# MSP430FR6972 register map
Registers are 16-bit, read-write, reset 0x0 unless marked. A register's access mark holds for its fields unless they carry their own. Offsets are from the block's base; [hi:lo] are bit positions; {n}, {i} and the like mark numbered series.

## USCI_B1_SPI_MODE
Base 0x00000680
0x00 UCB1CTL1_SPI 8-bit — USCI B1 Control Register 1
0x01 UCB1CTL0_SPI 8-bit — USCI B1 Control Register 0
0x06 UCB1BR0_SPI 8-bit — USCI B1 Baud Rate 0
0x07 UCB1BR1_SPI 8-bit — USCI B1 Baud Rate 1
0x0C UCB1RXBUF_SPI — USCI B1 Receive Buffer
0x0E UCB1TXBUF_SPI — USCI B1 Transmit Buffer
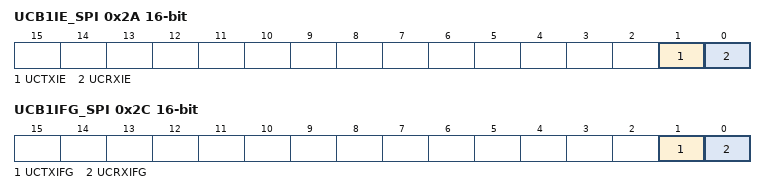
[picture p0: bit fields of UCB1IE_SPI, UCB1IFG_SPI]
0x2A UCB1IE_SPI — USCI B1 Interrupt Enable Register
  [1] UCTXIE — USCI Transmit Interrupt Enable
  [0] UCRXIE — USCI Receive Interrupt Enable
0x2C UCB1IFG_SPI — USCI B1 Interrupt Flags Register
  [1] UCTXIFG — SPI Transmit Interrupt Flag
  [0] UCRXIFG — SPI Receive Interrupt Flag
0x2E UCB1IV_SPI — USCI B1 Interrupt Vector Register

## LCD_C
Base 0x00000A00
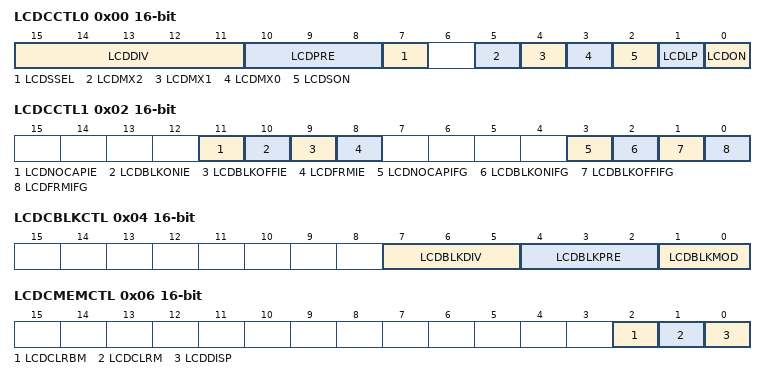
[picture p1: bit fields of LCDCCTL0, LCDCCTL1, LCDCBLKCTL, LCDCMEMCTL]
0x00 LCDCCTL0 — LCD_C Control Register 0
  [15:11] LCDDIV — LCD_C LCD frequency divider Bit: 0
    {v}=LCD_C LCD frequency divider: /{v+1} (v=0..31)
  [10:8] LCDPRE — LCD_C LCD frequency pre-scaler Bit: 0
    0=LCD_C LCD frequency pre-scaler: /1; 1=LCD_C LCD frequency pre-scaler: /2; 2=LCD_C LCD frequency pre-scaler: /4; 3=LCD_C LCD frequency pre-scaler: /8; 4=LCD_C LCD frequency pre-scaler: /16; 5=LCD_C LCD frequency pre-scaler: /32
  [7] LCDSSEL — LCD_C Clock Select
  [5] LCDMX2 — LCD_C Mux Rate Bit: 2
  [4] LCDMX1 — LCD_C Mux Rate Bit: 1
  [3] LCDMX0 — LCD_C Mux Rate Bit: 0
  [2] LCDSON — LCD_C LCD Segments On
  [1] LCDLP — LCD_C Low Power Waveform
  [0] LCDON — LCD_C LCD On
0x02 LCDCCTL1 — LCD_C Control Register 1
  [11] LCDNOCAPIE — LCD_C No cpacitance connected interrupt enable
  [10] LCDBLKONIE — LCD_C LCD blinking on interrupt flag
  [9] LCDBLKOFFIE — LCD_C LCD blinking off interrupt flag
  [8] LCDFRMIE — LCD_C LCD frame interrupt enable
  [3] LCDNOCAPIFG — LCD_C No cpacitance connected interrupt flag
  [2] LCDBLKONIFG — LCD_C LCD blinking on interrupt flag
  [1] LCDBLKOFFIFG — LCD_C LCD blinking off interrupt flag
  [0] LCDFRMIFG — LCD_C LCD frame interrupt flag
0x04 LCDCBLKCTL — LCD_C blinking control register
  [7:5] LCDBLKDIV — LCD_C Clock divider for blinking frequency Bit: 0
    {v}=LCD_C Clock divider for blinking frequency: {v} (v=0..7)
  [4:2] LCDBLKPRE — LCD_C Clock pre-scaler for blinking frequency Bit: 0
    {v}=LCD_C Clock pre-scaler for blinking frequency: {v} (v=0..7)
  [1:0] LCDBLKMOD — LCD_C Blinking mode Bit: 0
    0=LCD_C Blinking mode: Off; 1=LCD_C Blinking mode: Individual; 2=LCD_C Blinking mode: All; 3=LCD_C Blinking mode: Switching
0x06 LCDCMEMCTL — LCD_C memory control register
  [2] LCDCLRBM — LCD_C Clear LCD blinking memory
  [1] LCDCLRM — LCD_C Clear LCD memory
  [0] LCDDISP — LCD_C LCD memory registers for display
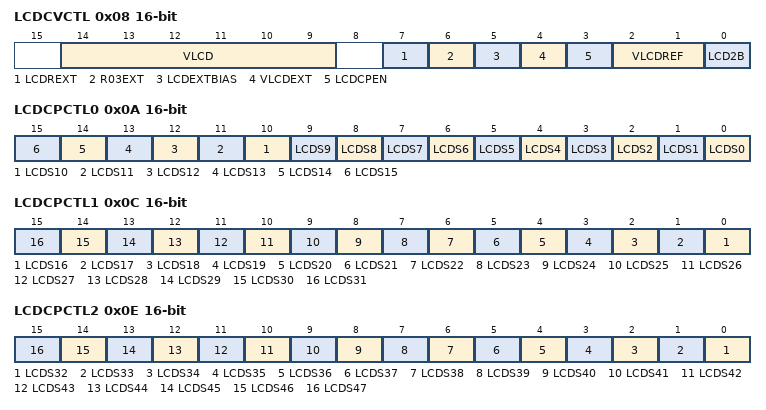
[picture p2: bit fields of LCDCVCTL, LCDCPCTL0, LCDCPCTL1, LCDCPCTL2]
0x08 LCDCVCTL — LCD_C Voltage Control Register
  [14:9] VLCD — VLCD select: 0
    0=Charge pump disabled; 1=VLCD = 2.60V; 2=VLCD = 2.66V; 3=VLCD = 2.72V; 4=VLCD = 2.78V; 5=VLCD = 2.84V; 6=VLCD = 2.90V; 7=VLCD = 2.96V; 8=VLCD = 3.02V; 9=VLCD = 3.08V; 10=VLCD = 3.14V; 11=VLCD = 3.20V; 12=VLCD = 3.26V; 13=VLCD = 3.32V; 14=VLCD = 3.38V; 15=VLCD = 3.44V
  [7] LCDREXT — Selects external connection for lowest LCD voltage.
  [6] R03EXT — Selects external connections for LCD mid voltages.
  [5] LCDEXTBIAS — V2 - V4 voltage select.
  [4] VLCDEXT — Select external source for VLCD.
  [3] LCDCPEN — LCD Voltage Charge Pump Enable.
  [2:1] VLCDREF — Selects reference voltage for regulated charge pump: 0
    0=Internal; 1=External
  [0] LCD2B — Selects 1/2 bias.
0x0A LCDCPCTL0 — LCD_C Port Control Register 0
  [n] LCDS{n} (n=0..15) — LCD Segment {n} enable.
0x0C LCDCPCTL1 — LCD_C Port Control Register 1
  [n-16] LCDS{n} (n=16..31) — LCD Segment {n} enable.
0x0E LCDCPCTL2 — LCD_C Port Control Register 2
  [n-32] LCDS{n} (n=32..47) — LCD Segment {n} enable.
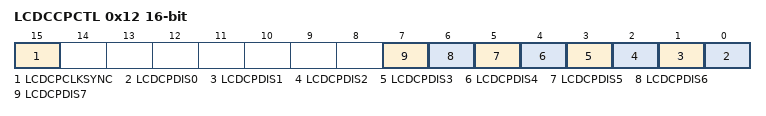
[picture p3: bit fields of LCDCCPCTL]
0x12 LCDCCPCTL — LCD_C Charge Pump Control Register 3
  [15] LCDCPCLKSYNC — LCD charge pump clock synchronization
  [n] LCDCPDIS{n} (n=0..7) — LCD charge pump disable
0x1E LCDCIV — LCD_C Interrupt Vector Register
{0x1F+i} LCDM{i} 8-bit (i=1..32) — LCD Memory {i}
{0x3F+i} LCDBM{i} 8-bit (i=1..22) — LCD Blinking Memory {i}
{0x1F+i} LCDM{i} 8-bit (alternate view of LCDBM{i-32}) (i=33..43) — LCD Memory {i}
